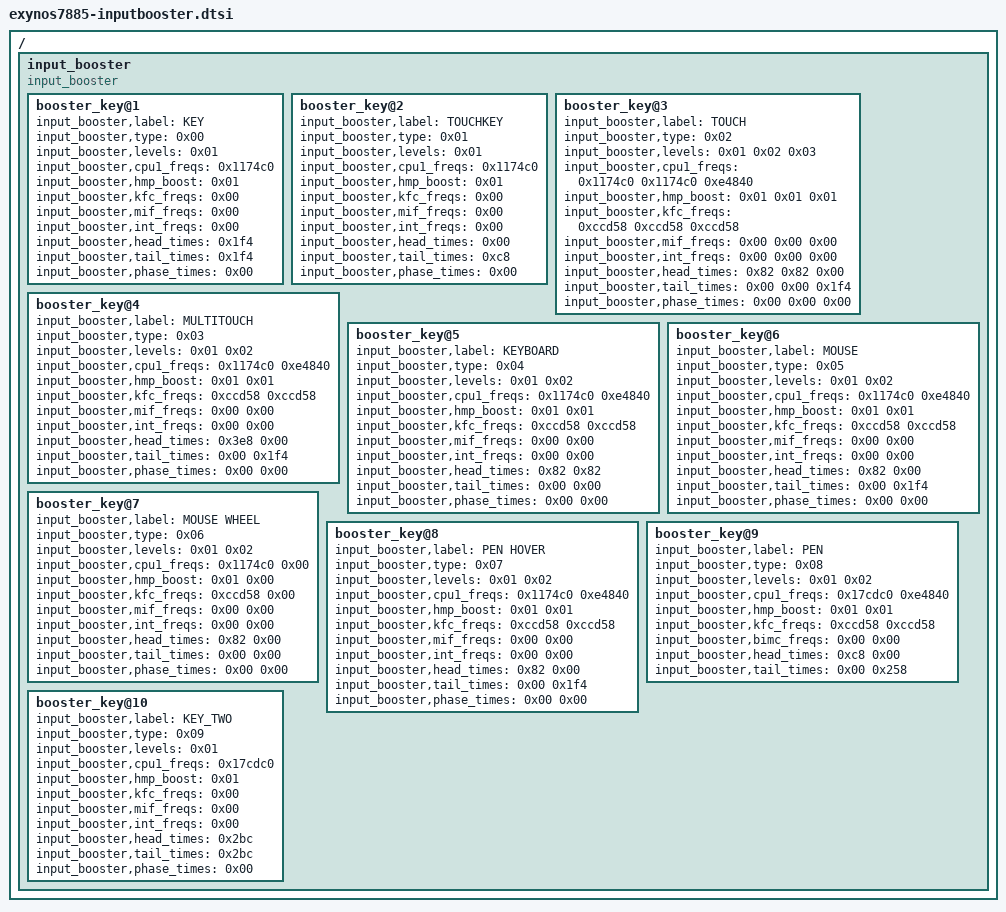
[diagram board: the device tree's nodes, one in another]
/ {
	input_booster {
		status = "okay";
		compatible = "input_booster";
		#address-cells = <0x01>;
		#size-cells = <0x00>;

		booster_key@1 {
			input_booster,label = "KEY";
			input_booster,type = <0x00>;
			input_booster,levels = <0x01>;
			input_booster,cpu1_freqs = <0x1174c0>;
			input_booster,hmp_boost = <0x01>;
			input_booster,kfc_freqs = <0x00>;
			input_booster,mif_freqs = <0x00>;
			input_booster,int_freqs = <0x00>;
			input_booster,head_times = <0x1f4>;
			input_booster,tail_times = <0x1f4>;
			input_booster,phase_times = <0x00>;
		};

		booster_key@2 {
			input_booster,label = "TOUCHKEY";
			input_booster,type = <0x01>;
			input_booster,levels = <0x01>;
			input_booster,cpu1_freqs = <0x1174c0>;
			input_booster,hmp_boost = <0x01>;
			input_booster,kfc_freqs = <0x00>;
			input_booster,mif_freqs = <0x00>;
			input_booster,int_freqs = <0x00>;
			input_booster,head_times = <0x00>;
			input_booster,tail_times = <0xc8>;
			input_booster,phase_times = <0x00>;
		};

		booster_key@3 {
			input_booster,label = "TOUCH";
			input_booster,type = <0x02>;
			input_booster,levels = <0x01 0x02 0x03>;
			input_booster,cpu1_freqs = <0x1174c0 0x1174c0 0xe4840>;
			input_booster,hmp_boost = <0x01 0x01 0x01>;
			input_booster,kfc_freqs = <0xccd58 0xccd58 0xccd58>;
			input_booster,mif_freqs = <0x00 0x00 0x00>;
			input_booster,int_freqs = <0x00 0x00 0x00>;
			input_booster,head_times = <0x82 0x82 0x00>;
			input_booster,tail_times = <0x00 0x00 0x1f4>;
			input_booster,phase_times = <0x00 0x00 0x00>;
		};

		booster_key@4 {
			input_booster,label = "MULTITOUCH";
			input_booster,type = <0x03>;
			input_booster,levels = <0x01 0x02>;
			input_booster,cpu1_freqs = <0x1174c0 0xe4840>;
			input_booster,hmp_boost = <0x01 0x01>;
			input_booster,kfc_freqs = <0xccd58 0xccd58>;
			input_booster,mif_freqs = <0x00 0x00>;
			input_booster,int_freqs = <0x00 0x00>;
			input_booster,head_times = <0x3e8 0x00>;
			input_booster,tail_times = <0x00 0x1f4>;
			input_booster,phase_times = <0x00 0x00>;
		};

		booster_key@5 {
			input_booster,label = "KEYBOARD";
			input_booster,type = <0x04>;
			input_booster,levels = <0x01 0x02>;
			input_booster,cpu1_freqs = <0x1174c0 0xe4840>;
			input_booster,hmp_boost = <0x01 0x01>;
			input_booster,kfc_freqs = <0xccd58 0xccd58>;
			input_booster,mif_freqs = <0x00 0x00>;
			input_booster,int_freqs = <0x00 0x00>;
			input_booster,head_times = <0x82 0x82>;
			input_booster,tail_times = <0x00 0x00>;
			input_booster,phase_times = <0x00 0x00>;
		};

		booster_key@6 {
			input_booster,label = "MOUSE";
			input_booster,type = <0x05>;
			input_booster,levels = <0x01 0x02>;
			input_booster,cpu1_freqs = <0x1174c0 0xe4840>;
			input_booster,hmp_boost = <0x01 0x01>;
			input_booster,kfc_freqs = <0xccd58 0xccd58>;
			input_booster,mif_freqs = <0x00 0x00>;
			input_booster,int_freqs = <0x00 0x00>;
			input_booster,head_times = <0x82 0x00>;
			input_booster,tail_times = <0x00 0x1f4>;
			input_booster,phase_times = <0x00 0x00>;
		};

		booster_key@7 {
			input_booster,label = "MOUSE WHEEL";
			input_booster,type = <0x06>;
			input_booster,levels = <0x01 0x02>;
			input_booster,cpu1_freqs = <0x1174c0 0x00>;
			input_booster,hmp_boost = <0x01 0x00>;
			input_booster,kfc_freqs = <0xccd58 0x00>;
			input_booster,mif_freqs = <0x00 0x00>;
			input_booster,int_freqs = <0x00 0x00>;
			input_booster,head_times = <0x82 0x00>;
			input_booster,tail_times = <0x00 0x00>;
			input_booster,phase_times = <0x00 0x00>;
		};

		booster_key@8 {
			input_booster,label = "PEN HOVER";
			input_booster,type = <0x07>;
			input_booster,levels = <0x01 0x02>;
			input_booster,cpu1_freqs = <0x1174c0 0xe4840>;
			input_booster,hmp_boost = <0x01 0x01>;
			input_booster,kfc_freqs = <0xccd58 0xccd58>;
			input_booster,mif_freqs = <0x00 0x00>;
			input_booster,int_freqs = <0x00 0x00>;
			input_booster,head_times = <0x82 0x00>;
			input_booster,tail_times = <0x00 0x1f4>;
			input_booster,phase_times = <0x00 0x00>;
		};

		booster_key@9 {
			input_booster,label = "PEN";
			input_booster,type = <0x08>;
			input_booster,levels = <0x01 0x02>;
			input_booster,cpu1_freqs = <0x17cdc0 0xe4840>;
			input_booster,hmp_boost = <0x01 0x01>;
			input_booster,kfc_freqs = <0xccd58 0xccd58>;
			input_booster,bimc_freqs = <0x00 0x00>;
			input_booster,head_times = <0xc8 0x00>;
			input_booster,tail_times = <0x00 0x258>;
		};

		booster_key@10 {
			input_booster,label = "KEY_TWO";
			input_booster,type = <0x09>;
			input_booster,levels = <0x01>;
			input_booster,cpu1_freqs = <0x17cdc0>;
			input_booster,hmp_boost = <0x01>;
			input_booster,kfc_freqs = <0x00>;
			input_booster,mif_freqs = <0x00>;
			input_booster,int_freqs = <0x00>;
			input_booster,head_times = <0x2bc>;
			input_booster,tail_times = <0x2bc>;
			input_booster,phase_times = <0x00>;
		};
	};
};
